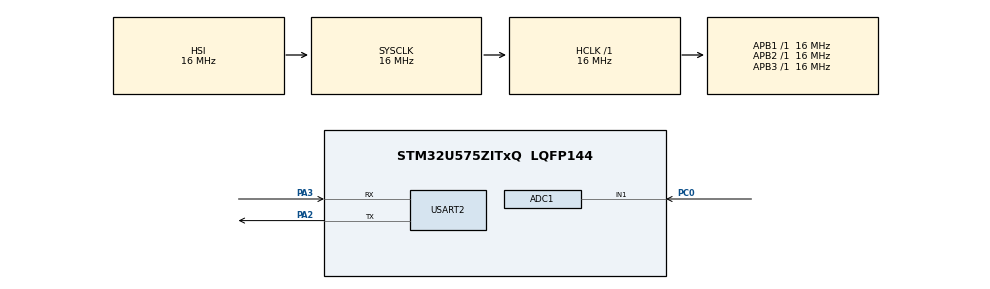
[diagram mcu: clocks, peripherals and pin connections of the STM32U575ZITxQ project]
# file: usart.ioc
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ADC1.NbrOfConversion=1
ADC1.master=1
CORTEX_M33_NS.userName=CORTEX_M33
Mcu.Family=STM32U5
Mcu.Name=STM32U575ZITxQ
Mcu.Package=LQFP144
NVIC.PriorityGroup=NVIC_PRIORITYGROUP_4
NVIC.USART2_IRQn=true\:0\:0\:false\:false\:true\:true\:true\:true
PA2.Mode=Asynchronous
PA2.Signal=USART2_TX
PA3.Mode=Asynchronous
PA3.Signal=USART2_RX
PC0.Mode=IN1-Single-Ended
PC0.Signal=ADC1_IN1
ProjectManager.HeapSize=0x200
ProjectManager.StackSize=0x400
ProjectManager.TargetToolchain=STM32CubeIDE
RCC.ADCFreq_Value=16000000
RCC.AHBFreq_Value=16000000
RCC.APB1Freq_Value=16000000
RCC.APB1TimFreq_Value=16000000
RCC.APB2Freq_Value=16000000
RCC.APB2TimFreq_Value=16000000
RCC.APB3Freq_Value=16000000
RCC.CortexFreq_Value=16000000
RCC.EPOD_VALUE=4000000
RCC.HCLKFreq_Value=16000000
RCC.HSE_VALUE=16000000
RCC.HSI48_VALUE=48000000
RCC.HSI_VALUE=16000000
RCC.LSE_VALUE=32768
RCC.LSIDIV_VALUE=32000
RCC.MSI_VALUE=4000000
RCC.SYSCLKFreq_VALUE=16000000
RCC.SYSCLKSource=RCC_SYSCLKSOURCE_HSI
RCC.USBFreq_Value=48000000
RCC.VCOOutputFreq_Value=516000000
USART2.VirtualMode-Asynchronous=VM_ASYNC
VP_LPBAMQUEUE_VS_QUEUE.Mode=QUEUEMODE
VP_LPBAM_VS_SIG1.Mode=SmartRun
VP_LPBAM_VS_SIG4.Mode=LPDMA1
VP_MEMORYMAP_VS_MEMORYMAP.Mode=CurAppReg
VP_PWR_VS_SECSignals.Mode=Security/Privilege
VP_PWR_Vdda.Mode=isolationVdda
board=custom

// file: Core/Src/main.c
/* USER CODE BEGIN Header */
/**
  ******************************************************************************
  * @file           : main.c
  * @brief          : Main program body
  ******************************************************************************
  * @attention
  *
  * Copyright (c) 2025 STMicroelectronics.
  * All rights reserved.
  *
  * This software is licensed under terms that can be found in the LICENSE file
  * in the root directory of this software component.
  * If no LICENSE file comes with this software, it is provided AS-IS.
  *
  ******************************************************************************
  */
/* USER CODE END Header */
#include "main.h"

ADC_HandleTypeDef hadc1;

UART_HandleTypeDef huart2;

/* USER CODE BEGIN PV */
char tx_data[] = "welcome to the world\r\n";
/* USER CODE END PV */

void SystemClock_Config(void);
static void MX_GPIO_Init(void);
static void MX_ADC1_Init(void);
static void MX_USART2_UART_Init(void);

int main(void)
{

  /* MCU Configuration--------------------------------------------------------*/

  /* Reset of all peripherals, Initializes the Flash interface and the Systick. */
  HAL_Init();

  /* Configure the system clock */
  SystemClock_Config();

  /* Initialize all configured peripherals */
  MX_GPIO_Init();
  MX_ADC1_Init();
  MX_USART2_UART_Init();

  /* Infinite loop */
  while (1)
  {

  }
}

void SystemClock_Config(void)
{
  RCC_OscInitTypeDef RCC_OscInitStruct = {0};
  RCC_ClkInitTypeDef RCC_ClkInitStruct = {0};

  /** Configure the main internal regulator output voltage
  */
  if (HAL_PWREx_ControlVoltageScaling(PWR_REGULATOR_VOLTAGE_SCALE4) != HAL_OK)
  {
    Error_Handler();
  }

  /** Initializes the CPU, AHB and APB buses clocks
  */
  RCC_OscInitStruct.OscillatorType = RCC_OSCILLATORTYPE_HSI;
  RCC_OscInitStruct.HSIState = RCC_HSI_ON;
  RCC_OscInitStruct.HSICalibrationValue = RCC_HSICALIBRATION_DEFAULT;
  RCC_OscInitStruct.PLL.PLLState = RCC_PLL_NONE;
  if (HAL_RCC_OscConfig(&RCC_OscInitStruct) != HAL_OK)
  {
    Error_Handler();
  }

  /** Initializes the CPU, AHB and APB buses clocks
  */
  RCC_ClkInitStruct.ClockType = RCC_CLOCKTYPE_HCLK|RCC_CLOCKTYPE_SYSCLK
                              |RCC_CLOCKTYPE_PCLK1|RCC_CLOCKTYPE_PCLK2
                              |RCC_CLOCKTYPE_PCLK3;
  RCC_ClkInitStruct.SYSCLKSource = RCC_SYSCLKSOURCE_HSI;
  RCC_ClkInitStruct.AHBCLKDivider = RCC_SYSCLK_DIV1;
  RCC_ClkInitStruct.APB1CLKDivider = RCC_HCLK_DIV1;
  RCC_ClkInitStruct.APB2CLKDivider = RCC_HCLK_DIV1;
  RCC_ClkInitStruct.APB3CLKDivider = RCC_HCLK_DIV1;

  if (HAL_RCC_ClockConfig(&RCC_ClkInitStruct, FLASH_LATENCY_1) != HAL_OK)
  {
    Error_Handler();
  }
}

static void MX_ADC1_Init(void)
{

  /** Common config
  */
  hadc1.Instance = ADC1;
  hadc1.Init.ClockPrescaler = ADC_CLOCK_ASYNC_DIV1;
  hadc1.Init.Resolution = ADC_RESOLUTION_14B;
  hadc1.Init.GainCompensation = 0;
  hadc1.Init.ScanConvMode = ADC_SCAN_DISABLE;
  hadc1.Init.EOCSelection = ADC_EOC_SINGLE_CONV;
  hadc1.Init.LowPowerAutoWait = DISABLE;
  hadc1.Init.ContinuousConvMode = DISABLE;
  hadc1.Init.NbrOfConversion = 1;
  hadc1.Init.DiscontinuousConvMode = DISABLE;
  hadc1.Init.DMAContinuousRequests = DISABLE;
  hadc1.Init.TriggerFrequencyMode = ADC_TRIGGER_FREQ_HIGH;
  hadc1.Init.Overrun = ADC_OVR_DATA_PRESERVED;
  hadc1.Init.LeftBitShift = ADC_LEFTBITSHIFT_NONE;
  hadc1.Init.ConversionDataManagement = ADC_CONVERSIONDATA_DR;
  hadc1.Init.OversamplingMode = DISABLE;
  if (HAL_ADC_Init(&hadc1) != HAL_OK)
  {
    Error_Handler();
  }

}

static void MX_USART2_UART_Init(void)
{

  huart2.Instance = USART2;
  huart2.Init.BaudRate = 115200;
  huart2.Init.WordLength = UART_WORDLENGTH_8B;
  huart2.Init.StopBits = UART_STOPBITS_1;
  huart2.Init.Parity = UART_PARITY_NONE;
  huart2.Init.Mode = UART_MODE_TX_RX;
  huart2.Init.HwFlowCtl = UART_HWCONTROL_NONE;
  huart2.Init.OverSampling = UART_OVERSAMPLING_16;
  huart2.Init.OneBitSampling = UART_ONE_BIT_SAMPLE_DISABLE;
  huart2.Init.ClockPrescaler = UART_PRESCALER_DIV1;
  huart2.AdvancedInit.AdvFeatureInit = UART_ADVFEATURE_NO_INIT;
  if (HAL_UART_Init(&huart2) != HAL_OK)
  {
    Error_Handler();
  }
  if (HAL_UARTEx_SetTxFifoThreshold(&huart2, UART_TXFIFO_THRESHOLD_1_8) != HAL_OK)
  {
    Error_Handler();
  }
  if (HAL_UARTEx_SetRxFifoThreshold(&huart2, UART_RXFIFO_THRESHOLD_1_8) != HAL_OK)
  {
    Error_Handler();
  }
  if (HAL_UARTEx_DisableFifoMode(&huart2) != HAL_OK)
  {
    Error_Handler();
  }

}

static void MX_GPIO_Init(void)
{

  /* GPIO Ports Clock Enable */
  __HAL_RCC_GPIOC_CLK_ENABLE();
  __HAL_RCC_GPIOA_CLK_ENABLE();

}

void Error_Handler(void)
{
  __disable_irq();
  while (1)
  {
  }
}
